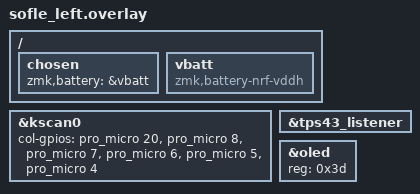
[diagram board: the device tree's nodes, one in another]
/*
 * Copyright (c) 2020 Ryan Cross
 *
 * SPDX-License-Identifier: MIT
 */

#include "sofle.dtsi"

&kscan0 {
    col-gpios
       = <&pro_micro 20 GPIO_ACTIVE_HIGH>
        , <&pro_micro 8 GPIO_ACTIVE_HIGH>
        , <&pro_micro 7 GPIO_ACTIVE_HIGH>
        , <&pro_micro 6 GPIO_ACTIVE_HIGH>
        , <&pro_micro 5 GPIO_ACTIVE_HIGH>
        , <&pro_micro 4 GPIO_ACTIVE_HIGH>
        ;
};

/ {
    chosen {
      zmk,battery = &vbatt;
    };

    vbatt: vbatt {
        compatible = "zmk,battery-nrf-vddh";
    };
};

&tps43_listener {
    status = "okay";
};

&oled {
    // Override the default 0x3c I2C address to the alternative 0x3d.
    reg = <0x3d>; 
    
    // Explicitly ensure the OLED node is active (redundant but safe)
    status = "okay";
};
